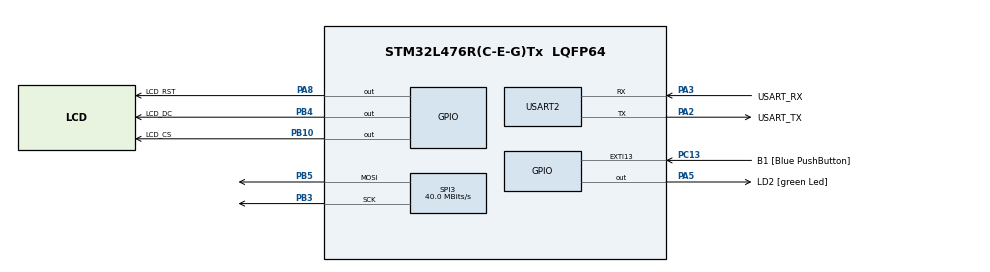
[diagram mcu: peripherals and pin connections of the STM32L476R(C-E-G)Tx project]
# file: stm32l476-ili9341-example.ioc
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Mcu.Family=STM32L4
Mcu.Name=STM32L476R(C-E-G)Tx
Mcu.Package=LQFP64
NVIC.PriorityGroup=NVIC_PRIORITYGROUP_4
PA13\ (JTMS-SWDIO).Mode=Serial_Wire
PA13\ (JTMS-SWDIO).Signal=SYS_JTMS-SWDIO
PA14\ (JTCK-SWCLK).Mode=Serial_Wire
PA14\ (JTCK-SWCLK).Signal=SYS_JTCK-SWCLK
PA2.GPIO_Label=USART_TX
PA2.GPIO_Mode=GPIO_MODE_AF_PP
PA2.GPIO_PuPd=GPIO_NOPULL
PA2.GPIO_Speed=GPIO_SPEED_FREQ_VERY_HIGH
PA2.Mode=Asynchronous
PA2.Signal=USART2_TX
PA3.GPIO_Label=USART_RX
PA3.GPIO_Mode=GPIO_MODE_AF_PP
PA3.GPIO_PuPd=GPIO_NOPULL
PA3.GPIO_Speed=GPIO_SPEED_FREQ_VERY_HIGH
PA3.Mode=Asynchronous
PA3.Signal=USART2_RX
PA5.GPIO_Label=LD2 [green Led]
PA5.GPIO_ModeDefaultOutputPP=GPIO_MODE_OUTPUT_PP
PA5.GPIO_PuPd=GPIO_NOPULL
PA5.GPIO_Speed=GPIO_SPEED_FREQ_VERY_HIGH
PA5.Signal=GPIO_Output
PA8.GPIO_Label=LCD_RST
PA8.GPIO_Speed=GPIO_SPEED_FREQ_VERY_HIGH
PA8.Signal=GPIO_Output
PB10.GPIO_Label=LCD_CS
PB10.GPIO_Speed=GPIO_SPEED_FREQ_VERY_HIGH
PB10.Signal=GPIO_Output
PB3\ (JTDO-TRACESWO).Mode=TX_Only_Simplex_Unidirect_Master
PB3\ (JTDO-TRACESWO).Signal=SPI3_SCK
PB4\ (NJTRST).GPIO_Label=LCD_DC
PB4\ (NJTRST).GPIO_Speed=GPIO_SPEED_FREQ_VERY_HIGH
PB4\ (NJTRST).Signal=GPIO_Output
PB5.Mode=TX_Only_Simplex_Unidirect_Master
PB5.Signal=SPI3_MOSI
PC13.GPIO_Label=B1 [Blue PushButton]
PC13.GPIO_ModeDefaultEXTI=GPIO_MODE_IT_FALLING
PC13.GPIO_PuPd=GPIO_NOPULL
PC13.Signal=GPXTI13
PC14-OSC32_IN\ (PC14).Mode=LSE-External-Oscillator
PC14-OSC32_IN\ (PC14).Signal=RCC_OSC32_IN
PC15-OSC32_OUT\ (PC15).Mode=LSE-External-Oscillator
PC15-OSC32_OUT\ (PC15).Signal=RCC_OSC32_OUT
PH0-OSC_IN\ (PH0).Signal=RCC_OSC_IN
PH1-OSC_OUT\ (PH1).Signal=RCC_OSC_OUT
ProjectManager.HeapSize=0x200
ProjectManager.StackSize=0x400
ProjectManager.TargetToolchain=STM32CubeIDE
RCC.ADCCLockSelection=RCC_ADCCLKSOURCE_SYSCLK
RCC.ADCFreq_Value=80000000
RCC.AHBFreq_Value=80000000
RCC.APB1Freq_Value=80000000
RCC.APB1TimFreq_Value=80000000
RCC.APB2Freq_Value=80000000
RCC.APB2TimFreq_Value=80000000
RCC.CortexFreq_Value=80000000
RCC.HCLKFreq_Value=80000000
RCC.HSE_VALUE=8000000
RCC.HSI_VALUE=16000000
RCC.MSIClockRange=RCC_MSIRANGE_8
RCC.MSI_VALUE=16000000
RCC.PLLN=10
RCC.PLLSourceVirtual=RCC_PLLSOURCE_HSI
RCC.PREFETCH_ENABLE=1
RCC.SYSCLKFreq_VALUE=80000000
RCC.SYSCLKSource=RCC_SYSCLKSOURCE_PLLCLK
RCC.USBFreq_Value=64000000
RCC.VCOOutputFreq_Value=160000000
SPI3.CalculateBaudRate=40.0 MBits/s
SPI3.DataSize=SPI_DATASIZE_8BIT
SPI3.Direction=SPI_DIRECTION_2LINES
SPI3.Mode=SPI_MODE_MASTER
SPI3.VirtualType=VM_MASTER
USART2.VirtualMode-Asynchronous=VM_ASYNC
board=NUCLEO-L476RG

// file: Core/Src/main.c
/* USER CODE BEGIN Header */
/**
  ******************************************************************************
  * @file           : main.c
  * @brief          : Main program body
  ******************************************************************************
  * @attention
  *
  * <h2><center>&copy; Copyright (c) 2019 STMicroelectronics.
  * All rights reserved.</center></h2>
  *
  * This software component is licensed by ST under BSD 3-Clause license,
  * the "License"; You may not use this file except in compliance with the
  * License. You may obtain a copy of the License at:
  *                        opensource.org/licenses/BSD-3-Clause
  *
  ******************************************************************************
  */
/* USER CODE END Header */

#include "main.h"
#include "spi.h"
#include "usart.h"
#include "gpio.h"

/* USER CODE BEGIN Includes */
#include "ILI9341_STM32_Driver.h"
/* USER CODE END Includes */

void SystemClock_Config(void);
/* USER CODE BEGIN PFP */
void demoAll();

/* USER CODE END PFP */

int main(void)
{

  /* MCU Configuration--------------------------------------------------------*/

  /* Reset of all peripherals, Initializes the Flash interface and the Systick. */

  LL_APB2_GRP1_EnableClock(LL_APB2_GRP1_PERIPH_SYSCFG);
  LL_APB1_GRP1_EnableClock(LL_APB1_GRP1_PERIPH_PWR);

  NVIC_SetPriorityGrouping(NVIC_PRIORITYGROUP_4);

  /* System interrupt init*/

  /* Configure the system clock */
  SystemClock_Config();

  /* Initialize all configured peripherals */
  MX_GPIO_Init();
  MX_USART2_UART_Init();
  MX_SPI3_Init();
  /* USER CODE BEGIN 2 */
  ILI9341_Init();
  LL_SYSTICK_EnableIT();

  /* USER CODE END 2 */

  /* Infinite loop */
  /* USER CODE BEGIN WHILE */
#pragma clang diagnostic push
#pragma clang diagnostic ignored "-Wmissing-noreturn"
  while (1)
  {
      demoAll();
    /* USER CODE END WHILE */

    /* USER CODE BEGIN 3 */
  }
#pragma clang diagnostic pop
  /* USER CODE END 3 */
}

void SystemClock_Config(void)
{
  LL_FLASH_SetLatency(LL_FLASH_LATENCY_4);

  if(LL_FLASH_GetLatency() != LL_FLASH_LATENCY_4)
  {
  Error_Handler();
  }
  LL_PWR_SetRegulVoltageScaling(LL_PWR_REGU_VOLTAGE_SCALE1);
  LL_RCC_HSI_Enable();

   /* Wait till HSI is ready */
  while(LL_RCC_HSI_IsReady() != 1)
  {

  }
  LL_RCC_HSI_SetCalibTrimming(16);
  LL_RCC_PLL_ConfigDomain_SYS(LL_RCC_PLLSOURCE_HSI, LL_RCC_PLLM_DIV_1, 10, LL_RCC_PLLR_DIV_2);
  LL_RCC_PLL_EnableDomain_SYS();
  LL_RCC_PLL_Enable();

   /* Wait till PLL is ready */
  while(LL_RCC_PLL_IsReady() != 1)
  {

  }
  LL_RCC_SetSysClkSource(LL_RCC_SYS_CLKSOURCE_PLL);

   /* Wait till System clock is ready */
  while(LL_RCC_GetSysClkSource() != LL_RCC_SYS_CLKSOURCE_STATUS_PLL)
  {

  }
  LL_RCC_SetAHBPrescaler(LL_RCC_SYSCLK_DIV_1);
  LL_RCC_SetAPB1Prescaler(LL_RCC_APB1_DIV_1);
  LL_RCC_SetAPB2Prescaler(LL_RCC_APB2_DIV_1);

  LL_Init1msTick(80000000);

  LL_SYSTICK_SetClkSource(LL_SYSTICK_CLKSOURCE_HCLK);
  LL_SetSystemCoreClock(80000000);
  LL_RCC_SetUSARTClockSource(LL_RCC_USART2_CLKSOURCE_PCLK1);
}

void Error_Handler(void)
{
}

/************************ (C) COPYRIGHT STMicroelectronics *****END OF FILE****/
